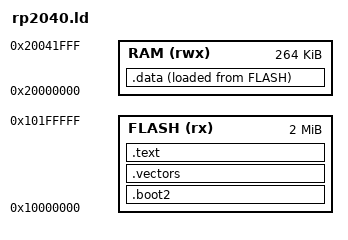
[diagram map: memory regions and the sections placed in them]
/*
 * rp2040.ld - RP2040 ベアメタルファームウェア用リンカスクリプト
 * 
 * SPDX-License-Identifier: BSD-3-Clause
 * 
 * 役割：
 *  各セクション（boot2、ベクタテーブル、コード、データ）を、フラッシュと
 *  SRAM のどこに、どう配置するかをするかをリンカに指示する。
 * 
 * 方針：
 *  - シンボル名は CMSIS（startup_ARMCM0plus.c）の命名に準拠する。
 *    学習ノート（docs/common/learning/linker.md）では _sdata などの
 *    教科書的な名前で説明しているが、実装では実務標準である CMSIS 名を使う。
 *    対応関係は各シンボル定義のコメントに記載する。
 *  - データ初期化は単純シンボル方式（__data_start__ 系）を採用。
 *    CMSIS のテーブル駆動方式（__copy_table_*）は、複数 RAM 領域が必要に
 *    なった場合に将来検討する（ADR-0003 参照）。
 *  - FLASH/RAM は実サイズで宣言する。領域予約や SRAM 分割が必要になれば見直す。
 * 
 * 対象：RP2040（Cortex-M0+、外付け 2MB QSPI フラッシュ、264KB SRAM）
 */

/* エントリポイント。組み込み（ベアメタル）では実際の起動は
 * boot2 → ベクタテーブルのリセットハンドラという流れだが、
 * ENTRY はデバッガ（GDB）が開始位置を知るために使う。
 * Reset_Handler の実体は crt0（段階2-C-4）で定義予定 */
ENTRY(Reset_Handler)

/* スタックサイズ（4KB）。RP2040 の SRAM は 264KB と潤沢なため余裕を持たせる。
 * スタックサイズは上位アドレスから下位へ伸びる（フルディセンディング）。 */
__STACK_SIZE = 0x1000;

/* ============================================================
 * MEMORY：利用可能なメモリ領域の定義
 * ============================================================ */
MEMORY
{
    /* 外付け QSPI フラッシュ。XIP（eXecute In Place）でコードを直接実行する。
     * rx = 読み取り + 実行可（書き込み不可）。 */
    FLASH   (rx)    : ORIGIN = 0x10000000, LENGTH = 2048k

    /* SRAM。読み書き可能なデータと、実行時に展開されるコード/データを置く。
     * rwx = 読み取り + 書き込み + 実行可。 */
    RAM     (rwx)   : ORIGIN = 0x20000000, LENGTH = 264k
}

/* ============================================================
 * SECTIONS：各セクションをどの領域にどう配置するか
 * ============================================================ */
SECTIONS
{
    /* --------------------------------------------------------
     * .boot2：第2段ブートローダ（フラッシュ先頭 256 バイト）
     * --------------------------------------------------------
     * RP2040 のブート ROM がフラッシュ先頭 256 バイトを読み、SRAMに
     * コピーして実行する。必ず先頭に配置する必要があるため最初に書く。
     * boot2 はコードから関数呼び出しで参照されない（ブート ROM が
     * ハードウェア的に読む）ため、--gc-sections で削除されないよう KEEP で保護する。 */
    .boot2 : {
        __boot2_start__ = .;
        KEEP(*(.boot2))
        __boot2_end__ = .;
    } > FLASH

    /* --------------------------------------------------------
     * .vectors：ベクタテーブル（boot2の直後）
     * --------------------------------------------------------
     * 初期スタックポインタ、リセットハンドラ、各種例外/割り込みハンドラの
     * アドレスを並べた表。CPU がハードウェア的にアドレスで参照するため、
     * KEEP で保護する。シンボル __VECTOR_TABLE は CMSIS の C スタートアップ
     * 実装で使われる名前。実体は crt0（段階2-C-4）で定義予定。 */
    .vectors : {
        __VECTOR_TABLE = .;
        KEEP(*(.vectors))
    } > FLASH

    /* --------------------------------------------------------
     * .text：プログラムコード
     * --------------------------------------------------------
     * -ffunction-sections でコンパイルすると関数ごとに .text.<関数名> という
     * 個別セクションになるため、.text* で全て拾う。
     * .rodata（読み取り先頭データ：文字列リテラル、const 変数）もフラッシュに置く。
     * これらは XIP でフラッシュから直接実行/読み取りするため LMA = VMA。 */
    .text : {
        *(.text)
        *(.text*)
        *(.rodata)
        *(.rodata*)
    } > FLASH

    /* .text/.rodata の終端。.data の初期値はこの直後のフラッシュに置かれる。
     * __etext は CMSIS の名前で「end of text」の意味。
     * 学習ノートの _sidata（.data 初期値の開始 = LMA）に相当する。 /
    __etext = .;

    /* --------------------------------------------------------
     * .data：初期値ありの可変データ
     * --------------------------------------------------------
     * VMA は RAM（実行時は SRAM 上で読み書きする）、
     * LMA は FLASH（初期値は電源断でも保持するためフラッシュに焼く）。
     * 「> RAM AT> FLASH」で VMA=RAM・LMA=FLASH を指定する。
     * 起動時に crt0 が __etext（LMA）から __data_start__〜__data_end__（VMA）へコピーする。
     * 
     * シンボル対応（CMSIS 名 / 学習ノートの名前）：
     *      __data_start__  / _sdata（.data 実体の開始、VMA）
     *      __data_end__    / _edata（.data 実体の終了、VMA） */
    .data : {
        . = ALIGN(4);
        __data_start__ = .;
        *(.data)
        *(.data*)
        . = ALIGN(4);
        __data_end__ = .;
    } > RAM AT> FLASH

    /* --------------------------------------------------------
     * .bss：初期値なし（ゼロ初期化）の可変データ
     * --------------------------------------------------------
     * VMA のみ（フラッシュに実体を持たない。全て 0 なのでサイズ情報だけ）。
     * 起動時に crt0 が __bss_start__〜__bss_end__ を 0 で埋める。
     * COMMON は初期化されていないグローバル変数の特殊な扱い（.bss の仲間）。
     * NOLOAD は「ロード時に内容を持たない」ことを明示する。
}
